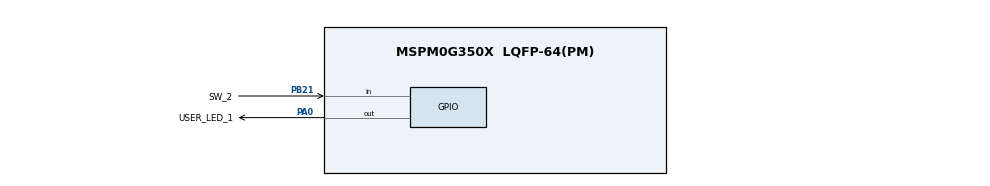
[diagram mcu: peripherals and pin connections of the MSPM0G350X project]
/**
 * @cliArgs --device "MSPM0G350X" --part "Default" --package "LQFP-64(PM)" --product "mspm0_sdk@2.05.01.01"
 * @versions {"tool":"1.24.0+4110"}
 */

/**
 * Import the modules used in this configuration.
 */
const GPIO          = scripting.addModule("/ti/driverlib/GPIO", {}, false);
const GPIO1         = GPIO.addInstance();
const GPIO2         = GPIO.addInstance();
const SYSCTL        = scripting.addModule("/ti/driverlib/SYSCTL");
const ProjectConfig = scripting.addModule("/ti/project_config/ProjectConfig");

/**
 * Write custom configuration values to the imported modules.
 */
GPIO1.$name                          = "GPIO_LEDS";
GPIO1.associatedPins.create(2);
GPIO1.associatedPins[0].$name        = "USER_LED_1";
GPIO1.associatedPins[0].assignedPin  = "0";
GPIO1.associatedPins[0].initialValue = "SET";
GPIO1.associatedPins[0].pin.$assign  = "PA0";
GPIO1.associatedPins[1].$name        = "GREEN";
GPIO1.associatedPins[1].assignedPort = "PORTB";
GPIO1.associatedPins[1].assignedPin  = "27";

const Board = scripting.addModule("/ti/driverlib/Board", {}, false);

GPIO2.$name                              = "GPIO_INPUT";
GPIO2.associatedPins[0].$name            = "SW_2";
GPIO2.associatedPins[0].assignedPort     = "PORTB";
GPIO2.associatedPins[0].assignedPin      = "21";
GPIO2.associatedPins[0].direction        = "INPUT";
GPIO2.associatedPins[0].internalResistor = "PULL_UP";
GPIO2.associatedPins[0].pin.$assign      = "PB21";

SYSCTL.clockTreeEn = true;

ProjectConfig.genDisable = true;

/**
 * Pinmux solution for unlocked pins/peripherals. This ensures that minor changes to the automatic solver in a future
 * version of the tool will not impact the pinmux you originally saw.  These lines can be completely deleted in order to
 * re-solve from scratch.
 */
GPIO1.associatedPins[1].pin.$suggestSolution = "PB27";
Board.peripheral.$suggestSolution            = "DEBUGSS";
Board.peripheral.swclkPin.$suggestSolution   = "PA20";
Board.peripheral.swdioPin.$suggestSolution   = "PA19";
